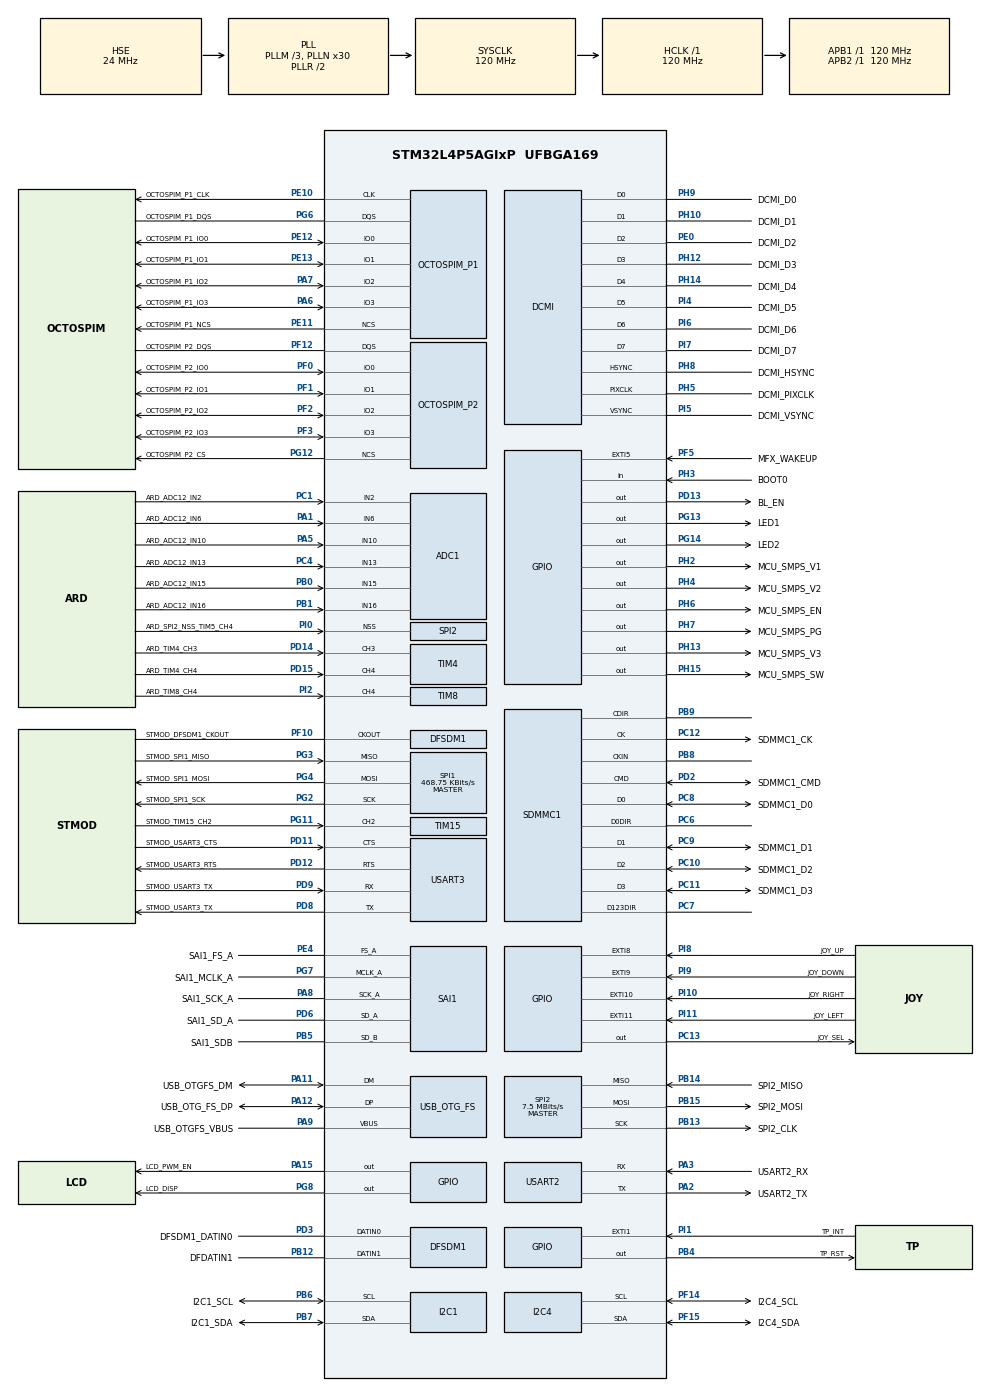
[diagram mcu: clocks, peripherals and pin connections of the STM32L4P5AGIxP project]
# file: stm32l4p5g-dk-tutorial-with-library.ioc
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ADC1.Channel-0\#ChannelRegularConversion=ADC_CHANNEL_13
ADC1.NbrOfConversionFlag=1
ADC1.OffsetNumber-0\#ChannelRegularConversion=ADC_OFFSET_NONE
ADC1.Rank-0\#ChannelRegularConversion=1
ADC1.SamplingTime-0\#ChannelRegularConversion=ADC_SAMPLETIME_2CYCLES_5
ADC1.master=1
I2C1.Timing=0x307075B1
I2C4.Timing=0x307075B1
Mcu.Family=STM32L4
Mcu.Name=STM32L4P5AGIxP
Mcu.Package=UFBGA169
NVIC.PriorityGroup=NVIC_PRIORITYGROUP_4
PA1.GPIO_Label=ARD_ADC12_IN6
PA1.Signal=ADCx_IN6
PA10.GPIO_Label=USB_OTGFS_ID
PA10.Signal=USB_OTG_FS_ID
PA11.GPIO_Label=USB_OTGFS_DM
PA11.Mode=Device_Only
PA11.Signal=USB_OTG_FS_DM
PA12.GPIO_Label=USB_OTG_FS_DP
PA12.Mode=Device_Only
PA12.Signal=USB_OTG_FS_DP
PA13\ (JTMS/SWDIO).GPIO_Label=SWDIO
PA13\ (JTMS/SWDIO).Mode=Trace_Asynchronous_SW
PA13\ (JTMS/SWDIO).Signal=SYS_JTMS-SWDIO
PA14\ (JTCK/SWCLK).GPIO_Label=SWCLK
PA14\ (JTCK/SWCLK).Mode=Trace_Asynchronous_SW
PA14\ (JTCK/SWCLK).Signal=SYS_JTCK-SWCLK
PA15\ (JTDI).GPIO_Label=LCD_PWM_EN
PA15\ (JTDI).Signal=GPIO_Output
PA2.GPIO_Label=USART2_TX
PA2.Mode=Asynchronous
PA2.Signal=USART2_TX
PA3.GPIO_Label=USART2_RX
PA3.Mode=Asynchronous
PA3.Signal=USART2_RX
PA4.GPIO_Label=LCD_CLK
PA4.Signal=LTDC_CLK
PA5.GPIO_Label=ARD_ADC12_IN10
PA5.Signal=ADCx_IN10
PA6.GPIO_Label=OCTOSPIM_P1_IO3
PA6.Mode=OCTOSPI2_IOH_Port1L
PA6.Signal=OCTOSPIM_P1_IO3
PA7.GPIO_Label=OCTOSPIM_P1_IO2
PA7.Mode=OCTOSPI2_IOH_Port1L
PA7.Signal=OCTOSPIM_P1_IO2
PA8.GPIO_Label=SAI1_SCK_A
PA8.Mode=SAI_A_MasterWithClock
PA8.Signal=SAI1_SCK_A
PA9.GPIO_Label=USB_OTGFS_VBUS
PA9.Mode=Activate_VBUS
PA9.Signal=USB_OTG_FS_VBUS
PB0.GPIO_Label=ARD_ADC12_IN15
PB0.Signal=ADCx_IN15
PB1.GPIO_Label=ARD_ADC12_IN16
PB1.Signal=ADCx_IN16
PB12.GPIO_Label=DFDATIN1
PB12.Signal=S_DATAIN1DFSDM1
PB13.GPIO_Label=SPI2_CLK
PB13.Mode=Full_Duplex_Master
PB13.Signal=SPI2_SCK
PB14.GPIO_Label=SPI2_MISO
PB14.Mode=Full_Duplex_Master
PB14.Signal=SPI2_MISO
PB15.GPIO_Label=SPI2_MOSI
PB15.Mode=Full_Duplex_Master
PB15.Signal=SPI2_MOSI
PB2.GPIO_Label=LCD_RTC_OUT2
PB2.Signal=LPTIM1_OUT
PB3\ (JTDO/TRACESWO).GPIO_Label=SWO
PB3\ (JTDO/TRACESWO).Mode=Trace_Asynchronous_SW
PB3\ (JTDO/TRACESWO).Signal=SYS_JTDO-SWO
PB4\ (NJTRST).GPIO_Label=TP_RST
PB4\ (NJTRST).Signal=GPIO_Output
PB5.GPIO_Label=SAI1_SDB
PB5.Mode=SAI_B_SyncSlave
PB5.Signal=SAI1_SD_B
PB6.GPIO_Label=I2C1_SCL
PB6.Mode=I2C
PB6.Signal=I2C1_SCL
PB7.GPIO_Label=I2C1_SDA
PB7.Mode=I2C
PB7.Signal=I2C1_SDA
PB8.Mode=SD_4_bits_Wide_bus_dir_voltage_converter
PB8.Signal=SDMMC1_CKIN
PB9.Mode=SD_4_bits_Wide_bus_dir_voltage_converter
PB9.Signal=SDMMC1_CDIR
PC0.GPIO_Label=LCD_DE
PC0.Signal=LTDC_DE
PC1.GPIO_Label=ARD_ADC12_IN2
PC1.Signal=ADCx_IN2
PC10.GPIO_Label=SDMMC1_D2
PC10.Mode=SD_4_bits_Wide_bus_dir_voltage_converter
PC10.Signal=SDMMC1_D2
PC11.GPIO_Label=SDMMC1_D3
PC11.Mode=SD_4_bits_Wide_bus_dir_voltage_converter
PC11.Signal=SDMMC1_D3
PC12.GPIO_Label=SDMMC1_CK
PC12.Mode=SD_4_bits_Wide_bus_dir_voltage_converter
PC12.Signal=SDMMC1_CK
PC13.GPIO_Label=JOY_SEL
PC13.Signal=GPIO_Output
PC14-OSC32_IN\ (PC14).Mode=LSE-External-Oscillator
PC14-OSC32_IN\ (PC14).Signal=RCC_OSC32_IN
PC15-OSC32_OUT\ (PC15).Mode=LSE-External-Oscillator
PC15-OSC32_OUT\ (PC15).Signal=RCC_OSC32_OUT
PC2.GPIO_Label=LCD_HSYNC
PC2.Signal=LTDC_HSYNC
PC4.GPIO_Label=ARD_ADC12_IN13
PC4.Signal=ADCx_IN13
PC6.Mode=SD_4_bits_Wide_bus_dir_voltage_converter
PC6.Signal=SDMMC1_D0DIR
PC7.Mode=SD_4_bits_Wide_bus_dir_voltage_converter
PC7.Signal=SDMMC1_D123DIR
PC8.GPIO_Label=SDMMC1_D0
PC8.Mode=SD_4_bits_Wide_bus_dir_voltage_converter
PC8.Signal=SDMMC1_D0
PC9.GPIO_Label=SDMMC1_D1
PC9.Mode=SD_4_bits_Wide_bus_dir_voltage_converter
PC9.Signal=SDMMC1_D1
PD10.GPIO_Label=STMOD_INT
PD10.Signal=EVENTOUT
PD11.GPIO_Label=STMOD_USART3_CTS
PD11.Mode=CTS_RTS
PD11.Signal=USART3_CTS
PD12.GPIO_Label=STMOD_USART3_RTS
PD12.Mode=CTS_RTS
PD12.Signal=USART3_RTS
PD13.GPIO_Label=BL_EN
PD13.Signal=GPIO_Output
PD14.GPIO_Label=ARD_TIM4_CH3
PD14.Signal=S_TIM4_CH3
PD15.GPIO_Label=ARD_TIM4_CH4
PD15.Signal=S_TIM4_CH4
PD2.GPIO_Label=SDMMC1_CMD
PD2.Mode=SD_4_bits_Wide_bus_dir_voltage_converter
PD2.Signal=SDMMC1_CMD
PD3.GPIO_Label=DFSDM1_DATIN0
PD3.Signal=S_DATAIN0DFSDM1
PD6.GPIO_Label=SAI1_SD_A
PD6.Mode=SAI_A_MasterWithClock
PD6.Signal=SAI1_SD_A
PD8.GPIO_Label=STMOD_USART3_TX
PD8.Mode=Asynchronous
PD8.Signal=USART3_TX
PD9.GPIO_Label=STMOD_USART3_TX
PD9.Mode=Asynchronous
PD9.Signal=USART3_RX
PE0.GPIO_Label=DCMI_D2
PE0.Mode=Slave_8_bits_External_Synchro
PE0.Signal=DCMI_D2
PE1.GPIO_Label=LCD_VSYNC
PE1.Signal=LTDC_VSYNC
PE10.GPIO_Label=OCTOSPIM_P1_CLK
PE10.Mode=O1_P1_CLK
PE10.Signal=OCTOSPIM_P1_CLK
PE11.GPIO_Label=OCTOSPIM_P1_NCS
PE11.Mode=OCTOSPI1_Port1_NCS
PE11.Signal=OCTOSPIM_P1_NCS
PE12.GPIO_Label=OCTOSPIM_P1_IO0
PE12.Mode=OCTOSPI2_IOH_Port1L
PE12.Signal=OCTOSPIM_P1_IO0
PE13.GPIO_Label=OCTOSPIM_P1_IO1
PE13.Mode=OCTOSPI2_IOH_Port1L
PE13.Signal=OCTOSPIM_P1_IO1
PE2.GPIO_Label=LCD_R7
PE2.Signal=LTDC_R7
PE3.GPIO_Label=LCD_R6
PE3.Signal=LTDC_R6
PE4.GPIO_Label=SAI1_FS_A
PE4.Mode=SAI_A_MasterWithClock
PE4.Signal=SAI1_FS_A
PE5.GPIO_Label=LCD_G7
PE5.Signal=LTDC_G7
PE6.GPIO_Label=LCD_G6
PE6.Signal=LTDC_G6
PE7.GPIO_Label=LCD_B6
PE7.Signal=LTDC_B6
PE8.GPIO_Label=LCD_B7
PE8.Signal=LTDC_B7
PF0.GPIO_Label=OCTOSPIM_P2_IO0
PF0.Mode=OCTOSPI1_IOL_Port2L
PF0.Signal=OCTOSPIM_P2_IO0
PF1.GPIO_Label=OCTOSPIM_P2_IO1
PF1.Mode=OCTOSPI1_IOL_Port2L
PF1.Signal=OCTOSPIM_P2_IO1
PF10.GPIO_Label=STMOD_DFSDM1_CKOUT
PF10.Signal=S_CKOUTDFSDM1
PF12.GPIO_Label=OCTOSPIM_P2_DQS
PF12.Mode=OCTOSPI2_Port2_DQS
PF12.Signal=OCTOSPIM_P2_DQS
PF14.GPIO_Label=I2C4_SCL
PF14.Mode=I2C
PF14.Signal=I2C4_SCL
PF15.GPIO_Label=I2C4_SDA
PF15.Mode=I2C
PF15.Signal=I2C4_SDA
PF2.GPIO_Label=OCTOSPIM_P2_IO2
PF2.Mode=OCTOSPI1_IOL_Port2L
PF2.Signal=OCTOSPIM_P2_IO2
PF3.GPIO_Label=OCTOSPIM_P2_IO3
PF3.Mode=OCTOSPI1_IOL_Port2L
PF3.Signal=OCTOSPIM_P2_IO3
PF5.GPIO_Label=MFX_WAKEUP
PF5.Signal=GPXTI5
PG11.GPIO_Label=STMOD_TIM15_CH2
PG11.Signal=S_TIM15_CH2
PG12.GPIO_Label=OCTOSPIM_P2_CS
PG12.Mode=OCTOSPI2_Port2_NCS
PG12.Signal=OCTOSPIM_P2_NCS
PG13.GPIO_Label=LED1
PG13.Signal=GPIO_Output
PG14.GPIO_Label=LED2
PG14.Signal=GPIO_Output
PG2.GPIO_Label=STMOD_SPI1_SCK
PG2.Mode=Full_Duplex_Master
PG2.Signal=SPI1_SCK
PG3.GPIO_Label=STMOD_SPI1_MISO
PG3.Mode=Full_Duplex_Master
PG3.Signal=SPI1_MISO
PG4.GPIO_Label=STMOD_SPI1_MOSI
PG4.Mode=Full_Duplex_Master
PG4.Signal=SPI1_MOSI
PG5.GPIO_Label=STMOD_SPI1_NSS
PG5.Signal=FMC_A15
PG6.GPIO_Label=OCTOSPIM_P1_DQS
PG6.Mode=OCTOSPI1_Port1_DQS
PG6.Signal=OCTOSPIM_P1_DQS
PG7.GPIO_Label=SAI1_MCLK_A
PG7.Mode=SAI_A_MasterWithClock
PG7.Signal=SAI1_MCLK_A
PG8.GPIO_Label=LCD_DISP
PG8.Signal=GPIO_Output
PH0-OSC_IN\ (PH0).Mode=HSE-External-Oscillator
PH0-OSC_IN\ (PH0).Signal=RCC_OSC_IN
PH1-OSC_OUT\ (PH1).Mode=HSE-External-Oscillator
PH1-OSC_OUT\ (PH1).Signal=RCC_OSC_OUT
PH10.GPIO_Label=DCMI_D1
PH10.Mode=Slave_8_bits_External_Synchro
PH10.Signal=DCMI_D1
PH12.GPIO_Label=DCMI_D3
PH12.Mode=Slave_8_bits_External_Synchro
PH12.Signal=DCMI_D3
PH13.GPIO_Label=MCU_SMPS_V3
PH13.Signal=GPIO_Output
PH14.GPIO_Label=DCMI_D4
PH14.Mode=Slave_8_bits_External_Synchro
PH14.Signal=DCMI_D4
PH15.GPIO_Label=MCU_SMPS_SW
PH15.Signal=GPIO_Output
PH2.GPIO_Label=MCU_SMPS_V1
PH2.Signal=GPIO_Output
PH3-BOOT0.GPIO_Label=BOOT0
PH3-BOOT0.Signal=GPIO_Input
PH4.GPIO_Label=MCU_SMPS_V2
PH4.Signal=GPIO_Output
PH5.GPIO_Label=DCMI_PIXCLK
PH5.Mode=Slave_8_bits_External_Synchro
PH5.Signal=DCMI_PIXCLK
PH6.GPIO_Label=MCU_SMPS_EN
PH6.Signal=GPIO_Output
PH7.GPIO_Label=MCU_SMPS_PG
PH7.Signal=GPIO_Output
PH8.GPIO_Label=DCMI_HSYNC
PH8.Mode=Slave_8_bits_External_Synchro
PH8.Signal=DCMI_HSYNC
PH9.GPIO_Label=DCMI_D0
PH9.Mode=Slave_8_bits_External_Synchro
PH9.Signal=DCMI_D0
PI0.GPIO_Label=ARD_SPI2_NSS_TIM5_CH4
PI0.Signal=SharedStack_PI0
PI0.Stacked=true
PI1.GPIO_Label=TP_INT
PI1.Signal=GPXTI1
PI10.GPIO_Label=JOY_RIGHT
PI10.Signal=GPXTI10
PI11.GPIO_Label=JOY_LEFT
PI11.Signal=GPXTI11
PI2.GPIO_Label=ARD_TIM8_CH4
PI2.Signal=S_TIM8_CH4
PI3.GPIO_Label=DCMI_D10
PI3.Signal=DCMI_D10
PI4.GPIO_Label=DCMI_D5
PI4.Mode=Slave_8_bits_External_Synchro
PI4.Signal=DCMI_D5
PI5.GPIO_Label=DCMI_VSYNC
PI5.Mode=Slave_8_bits_External_Synchro
PI5.Signal=DCMI_VSYNC
PI6.GPIO_Label=DCMI_D6
PI6.Mode=Slave_8_bits_External_Synchro
PI6.Signal=DCMI_D6
PI7.GPIO_Label=DCMI_D7
PI7.Mode=Slave_8_bits_External_Synchro
PI7.Signal=DCMI_D7
PI8.GPIO_Label=JOY_UP
PI8.Signal=GPXTI8
PI9.GPIO_Label=JOY_DOWN
PI9.Signal=GPXTI9
ProjectManager.HeapSize=0x200
ProjectManager.StackSize=0x400
ProjectManager.TargetToolchain=STM32CubeIDE
RCC.ADCFreq_Value=48000000
RCC.AHBFreq_Value=120000000
RCC.APB1Freq_Value=120000000
RCC.APB1TimFreq_Value=120000000
RCC.APB2Freq_Value=120000000
RCC.APB2TimFreq_Value=120000000
RCC.CortexFreq_Value=120000000
RCC.HCLKFreq_Value=120000000
RCC.HSE_VALUE=24000000
RCC.HSI48_VALUE=48000000
RCC.HSI_VALUE=16000000
RCC.MSI_VALUE=4000000
RCC.PLLM1=3
RCC.PLLM2=3
RCC.PLLN=30
RCC.PLLSAI1N=12
RCC.PLLSourceVirtual=RCC_PLLSOURCE_HSE
RCC.SYSCLKFreq_VALUE=120000000
RCC.SYSCLKSource=RCC_SYSCLKSOURCE_PLLCLK
RCC.USBFreq_Value=48000000
RCC.VCOOutputFreq_Value=240000000
SAI1.ErrorAudioFreq-SAI_A_MasterWithClock=-81.39 %
SAI1.Instance-SAI_A_MasterWithClock=SAI$Index_Block_A
SAI1.Instance-SAI_B_SyncSlave=SAI$Index_Block_B
SAI1.MClockEnable-SAI_A_MasterWithClock=SAI_MASTERCLOCK_ENABLE
SAI1.RealAudioFreq-SAI_A_MasterWithClock=35.714 KHz
SAI1.VirtualMode-SAI_A_MasterWithClock=VM_MASTER
SAI1.VirtualMode-SAI_B_SyncSlave=VM_SLAVE
SH.ADCx_IN10.0=ADC1_IN10,IN10-Single-Ended
SH.ADCx_IN13.0=ADC1_IN13,IN13-Single-Ended
SH.ADCx_IN15.0=ADC1_IN15,IN15-Single-Ended
SH.ADCx_IN16.0=ADC1_IN16,IN16-Single-Ended
SH.ADCx_IN2.0=ADC1_IN2,IN2-Single-Ended
SH.ADCx_IN6.0=ADC1_IN6,IN6-Single-Ended
SH.FMC_A15.0=FMC_A15
SH.S_CKOUTDFSDM1.0=DFSDM1_CKOUT,CKOUT
SH.S_CKOUTDFSDM1.1=DFSDM1_CKOUT,PDM_SPI_input_from_ch0_and_internal_clock
SH.S_CKOUTDFSDM1.2=DFSDM1_CKOUT,PDM_SPI_input_from_ch1_and_internal_clock
SH.S_DATAIN0DFSDM1.0=DFSDM1_DATIN0,PDM_SPI_input_from_ch0_and_internal_clock
SH.S_DATAIN1DFSDM1.0=DFSDM1_DATIN1,PDM_SPI_input_from_ch1_and_internal_clock
SH.S_TIM15_CH2.0=TIM15_CH2,Input_Capture2_from_TI2
SH.S_TIM4_CH3.0=TIM4_CH3,Input_Capture3_from_TI3
SH.S_TIM4_CH4.0=TIM4_CH4,Input_Capture4_from_TI4
SH.S_TIM8_CH4.0=TIM8_CH4,Input_Capture4_from_TI4
SH.SharedStack_PI0.0=SPI2_NSS,NSS_Signal_Hard_Input
SH.SharedStack_PI0.1=TIM5_CH4
SPI1.BaudRatePrescaler=SPI_BAUDRATEPRESCALER_256
SPI1.CalculateBaudRate=468.75 KBits/s
SPI1.Direction=SPI_DIRECTION_2LINES
SPI1.Mode=SPI_MODE_MASTER
SPI1.VirtualType=VM_MASTER
SPI2.BaudRatePrescaler=SPI_BAUDRATEPRESCALER_16
SPI2.CalculateBaudRate=7.5 MBits/s
SPI2.Direction=SPI_DIRECTION_2LINES
SPI2.Mode=SPI_MODE_MASTER
SPI2.VirtualNSS=VM_NSSHARD
SPI2.VirtualType=VM_MASTER
TIM15.Channel-Input_Capture2_from_TI2=TIM_CHANNEL_2
TIM4.Channel-Input_Capture3_from_TI3=TIM_CHANNEL_3
TIM4.Channel-Input_Capture4_from_TI4=TIM_CHANNEL_4
TIM8.Channel-Input_Capture4_from_TI4=TIM_CHANNEL_4
USART2.VirtualMode-Asynchronous=VM_ASYNC
USART3.VirtualMode-Asynchronous=VM_ASYNC
USB_OTG_FS.VirtualMode=Device_Only
VP_OCTOSPI1_VS_octo.Mode=octo_mode
VP_OCTOSPI2_VS_octo.Mode=octo_mode
board=STM32L4P5G-DK

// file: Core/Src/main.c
/* USER CODE BEGIN Header */
/**
  ******************************************************************************
  * @file           : main.c
  * @brief          : Main program body
  ******************************************************************************
  * @attention
  *
  * <h2><center>&copy; Copyright (c) 2020 STMicroelectronics.
  * All rights reserved.</center></h2>
  *
  * This software component is licensed by ST under BSD 3-Clause license,
  * the "License"; You may not use this file except in compliance with the
  * License. You may obtain a copy of the License at:
  *                        opensource.org/licenses/BSD-3-Clause
  *
  ******************************************************************************
  */
/* USER CODE END Header */
#include "main.h"

/* USER CODE BEGIN Includes */
// C Includes
#include <stdbool.h>
#include <stddef.h>
#include <stdint.h>
#include <stdio.h>
#include <stdlib.h>
#include <string.h>

// 3rd-Party Includes
#include <bme680.h>
#include <note.h>
/* USER CODE END Includes */

/* USER CODE BEGIN PTD */
#define DELAY_PERIOD_MS (15*1000) // 15 seconds
#define NOTE_I2C_BUFFER_SIZE 0xFF

#ifndef PRODUCT_UID
#pragma info "PRODUCT_UID is not defined in this example. Please ensure your Notecard has a product identifier set before running this example or define it in code here. Please see https://bit.ly/product-uid for more details."
#define PRODUCT_UID ""      /* com.mycompany.myname:project */

#endif

/* USER CODE END PTD */

ADC_HandleTypeDef hadc1;

DCMI_HandleTypeDef hdcmi;

DFSDM_Channel_HandleTypeDef hdfsdm1_channel0;
DFSDM_Channel_HandleTypeDef hdfsdm1_channel1;

I2C_HandleTypeDef hi2c1;
I2C_HandleTypeDef hi2c4;

OSPI_HandleTypeDef hospi1;
OSPI_HandleTypeDef hospi2;

SAI_HandleTypeDef hsai_BlockA1;
SAI_HandleTypeDef hsai_BlockB1;

SD_HandleTypeDef hsd1;

SPI_HandleTypeDef hspi1;
SPI_HandleTypeDef hspi2;

TIM_HandleTypeDef htim4;
TIM_HandleTypeDef htim8;
TIM_HandleTypeDef htim15;

UART_HandleTypeDef huart2;
UART_HandleTypeDef huart3;

PCD_HandleTypeDef hpcd_USB_OTG_FS;

/* USER CODE BEGIN PV */
// Data used during BME680 sampling
struct bme680_dev gas_sensor;
char i2c_reading_buf[100];
int8_t rslt = BME680_OK;

// Necessary for Notecard I/O functionality
bool i2c4Initialized = false;
/* USER CODE END PV */

void SystemClock_Config(void);
static void MX_GPIO_Init(void);
static void MX_ADC1_Init(void);
static void MX_DCMI_Init(void);
static void MX_DFSDM1_Init(void);
static void MX_I2C1_Init(void);
static void MX_I2C4_Init(void);
static void MX_OCTOSPI1_Init(void);
static void MX_OCTOSPI2_Init(void);
static void MX_SAI1_Init(void);
static void MX_SDMMC1_SD_Init(void);
static void MX_SPI1_Init(void);
static void MX_SPI2_Init(void);
static void MX_TIM4_Init(void);
static void MX_TIM8_Init(void);
static void MX_TIM15_Init(void);
static void MX_USART2_UART_Init(void);
static void MX_USART3_UART_Init(void);
static void MX_USB_OTG_FS_PCD_Init(void);
/* USER CODE BEGIN PFP */
void MX_I2C4_DeInit(void);

// BME680 Forward Declarations
int8_t bme680I2cRead(uint8_t dev_id, uint8_t reg_addr, uint8_t *reg_data, uint16_t len);
int8_t bme680I2cWrite(uint8_t dev_id, uint8_t reg_addr, uint8_t *reg_data, uint16_t len);

// Note I2C Interface
bool noteI2CReset(uint16_t dev_addr);
const char * noteI2CTransmit(uint16_t dev_addr, uint8_t* pBuffer, uint16_t size);
const char * noteI2CReceive(uint16_t dev_addr, uint8_t* pBuffer, uint16_t size, uint32_t *available);

// Serial Debug
size_t noteDebugSerialOutput(const char *message);
/* USER CODE END PFP */

int main(void)
{

  /* MCU Configuration--------------------------------------------------------*/

  /* Reset of all peripherals, Initializes the Flash interface and the Systick. */
  HAL_Init();

  /* Configure the system clock */
  SystemClock_Config();

  /* Initialize all configured peripherals */
  MX_GPIO_Init();
  MX_ADC1_Init();
  MX_DCMI_Init();
  MX_DFSDM1_Init();
  MX_I2C1_Init();
  MX_I2C4_Init();
  MX_OCTOSPI1_Init();
  MX_OCTOSPI2_Init();
  MX_SAI1_Init();
  MX_SDMMC1_SD_Init();
  MX_SPI1_Init();
  MX_SPI2_Init();
  MX_TIM4_Init();
  MX_TIM8_Init();
  MX_TIM15_Init();
  MX_USART2_UART_Init();
  MX_USART3_UART_Init();
  MX_USB_OTG_FS_PCD_Init();
  /* USER CODE BEGIN 2 */
  // Configure the BME680 driver
  gas_sensor.dev_id = BME680_I2C_ADDR_PRIMARY;
  gas_sensor.intf = BME680_I2C_INTF;
  gas_sensor.read = bme680I2cRead;
  gas_sensor.write = bme680I2cWrite;
  gas_sensor.delay_ms = HAL_Delay;
  gas_sensor.amb_temp = 25;

  // Initialize the driver
  if (bme680_init(&gas_sensor) != BME680_OK) {
    char bme_msg[] = "BME680 Initialization Error\\r\\n";
    noteDebugSerialOutput(bme_msg);
  } else {
    char bme_msg[] = "BME680 Initialized and Ready\\r\\n";
    noteDebugSerialOutput(bme_msg);
  }

  // Select desired oversampling rates
  gas_sensor.tph_sett.os_hum = BME680_OS_2X;
  gas_sensor.tph_sett.os_pres = BME680_OS_4X;
  gas_sensor.tph_sett.os_temp = BME680_OS_8X;

  // Set sensor to "always on"
  gas_sensor.power_mode = BME680_FORCED_MODE;

  // Set oversampling settings
  uint8_t required_settings = (BME680_OST_SEL | BME680_OSP_SEL | BME680_OSH_SEL);
  rslt = bme680_set_sensor_settings(required_settings, &gas_sensor);

  // Set sensor mode
  rslt = bme680_set_sensor_mode(&gas_sensor);

  // Query minimum sampling period
  uint16_t min_sampling_period;
  bme680_get_profile_dur(&min_sampling_period, &gas_sensor);

  // Sampling results variable
  struct bme680_field_data data;

  // Set Notecard System Interface
  NoteSetFn(malloc, free, HAL_Delay, HAL_GetTick);

  // Set Notecard I2C Interface
  NoteSetFnI2C(NOTE_I2C_ADDR_DEFAULT, NOTE_I2C_BUFFER_SIZE, noteI2CReset, noteI2CTransmit, noteI2CReceive);

  // Configure device with ProductUID
  J *req = NoteNewRequest("hub.set");
  if (PRODUCT_UID[0]) {
    JAddStringToObject(req, "product", PRODUCT_UID);
  }
  JAddStringToObject(req, "mode", "continuous");
  NoteRequest(req);
  /* USER CODE END 2 */

  /* Infinite loop */
  /* USER CODE BEGIN WHILE */
  while (1)
  {
	  // Allow BME680 to sample environment
	  HAL_Delay(min_sampling_period);

	  // Query the sample data
	  rslt = bme680_get_sensor_data(&data, &gas_sensor);

	  // Format results into a human readable string
	  sprintf(i2c_reading_buf,
	    "T: %u.%u degC, H %u.%u %%rH\\r\\n",
	    (unsigned int)data.temperature / 100,
	    (unsigned int)data.temperature % 100,
	    (unsigned int)data.humidity / 1000,
	    (unsigned int)data.humidity % 1000);

	  // Publish result to connected PC
	  noteDebugSerialOutput(i2c_reading_buf);

	  // Queue sensor reading to Notecard
	  J *req = NoteNewRequest("note.add");
	  if (req != NULL) {
	    JAddStringToObject(req, "file", "sensors.qo");
	    JAddBoolToObject(req, "sync", true);
	    J *body = JCreateObject();
	    if (body != NULL) {
	      JAddNumberToObject(body, "temp", data.temperature / 100.0);
	      JAddNumberToObject(body, "humidity", data.humidity / 1000.0);
	      JAddItemToObject(req, "body", body);
	    }
	    NoteRequest(req);
	  }

	  // Wait between samples
	  HAL_Delay(DELAY_PERIOD_MS);

	  // Request the next sample
	  if (gas_sensor.power_mode == BME680_FORCED_MODE) {
	    rslt = bme680_set_sensor_mode(&gas_sensor);
	  }
    /* USER CODE END WHILE */

  }
}

void SystemClock_Config(void)
{
  RCC_OscInitTypeDef RCC_OscInitStruct = {0};
  RCC_ClkInitTypeDef RCC_ClkInitStruct = {0};
  RCC_PeriphCLKInitTypeDef PeriphClkInit = {0};

  /** Configure the main internal regulator output voltage
  */
  if (HAL_PWREx_ControlVoltageScaling(PWR_REGULATOR_VOLTAGE_SCALE1_BOOST) != HAL_OK)
  {
    Error_Handler();
  }
  /** Initializes the RCC Oscillators according to the specified parameters
  * in the RCC_OscInitTypeDef structure.
  */
  RCC_OscInitStruct.OscillatorType = RCC_OSCILLATORTYPE_HSE;
  RCC_OscInitStruct.HSEState = RCC_HSE_ON;
  RCC_OscInitStruct.PLL.PLLState = RCC_PLL_ON;
  RCC_OscInitStruct.PLL.PLLSource = RCC_PLLSOURCE_HSE;
  RCC_OscInitStruct.PLL.PLLM = 3;
  RCC_OscInitStruct.PLL.PLLN = 30;
  RCC_OscInitStruct.PLL.PLLP = RCC_PLLP_DIV7;
  RCC_OscInitStruct.PLL.PLLQ = RCC_PLLQ_DIV2;
  RCC_OscInitStruct.PLL.PLLR = RCC_PLLR_DIV2;
  if (HAL_RCC_OscConfig(&RCC_OscInitStruct) != HAL_OK)
  {
    Error_Handler();
  }
  /** Initializes the CPU, AHB and APB buses clocks
  */
  RCC_ClkInitStruct.ClockType = RCC_CLOCKTYPE_HCLK|RCC_CLOCKTYPE_SYSCLK
                              |RCC_CLOCKTYPE_PCLK1|RCC_CLOCKTYPE_PCLK2;
  RCC_ClkInitStruct.SYSCLKSource = RCC_SYSCLKSOURCE_PLLCLK;
  RCC_ClkInitStruct.AHBCLKDivider = RCC_SYSCLK_DIV1;
  RCC_ClkInitStruct.APB1CLKDivider = RCC_HCLK_DIV1;
  RCC_ClkInitStruct.APB2CLKDivider = RCC_HCLK_DIV1;

  if (HAL_RCC_ClockConfig(&RCC_ClkInitStruct, FLASH_LATENCY_5) != HAL_OK)
  {
    Error_Handler();
  }
  PeriphClkInit.PeriphClockSelection = RCC_PERIPHCLK_USART2|RCC_PERIPHCLK_USART3
                              |RCC_PERIPHCLK_SAI1|RCC_PERIPHCLK_I2C1
                              |RCC_PERIPHCLK_I2C4|RCC_PERIPHCLK_DFSDM1
                              |RCC_PERIPHCLK_USB|RCC_PERIPHCLK_SDMMC1
                              |RCC_PERIPHCLK_ADC|RCC_PERIPHCLK_OSPI;
  PeriphClkInit.Usart2ClockSelection = RCC_USART2CLKSOURCE_PCLK1;
  PeriphClkInit.Usart3ClockSelection = RCC_USART3CLKSOURCE_PCLK1;
  PeriphClkInit.I2c1ClockSelection = RCC_I2C1CLKSOURCE_PCLK1;
  PeriphClkInit.I2c4ClockSelection = RCC_I2C4CLKSOURCE_PCLK1;
  PeriphClkInit.Sai1ClockSelection = RCC_SAI1CLKSOURCE_PLLSAI1;
  PeriphClkInit.AdcClockSelection = RCC_ADCCLKSOURCE_PLLSAI1;
  PeriphClkInit.Dfsdm1ClockSelection = RCC_DFSDM1CLKSOURCE_PCLK;
  PeriphClkInit.OspiClockSelection = RCC_OSPICLKSOURCE_SYSCLK;
  PeriphClkInit.UsbClockSelection = RCC_USBCLKSOURCE_PLLSAI1;
  PeriphClkInit.Sdmmc1ClockSelection = RCC_SDMMC1CLKSOURCE_PLLP;
  PeriphClkInit.PLLSAI1.PLLSAI1Source = RCC_PLLSOURCE_HSE;
  PeriphClkInit.PLLSAI1.PLLSAI1M = 3;
  PeriphClkInit.PLLSAI1.PLLSAI1N = 12;
  PeriphClkInit.PLLSAI1.PLLSAI1P = RCC_PLLP_DIV7;
  PeriphClkInit.PLLSAI1.PLLSAI1Q = RCC_PLLQ_DIV2;
  PeriphClkInit.PLLSAI1.PLLSAI1R = RCC_PLLR_DIV2;
  PeriphClkInit.PLLSAI1.PLLSAI1ClockOut = RCC_PLLSAI1_SAI1CLK|RCC_PLLSAI1_48M2CLK
                              |RCC_PLLSAI1_ADC1CLK;
  if (HAL_RCCEx_PeriphCLKConfig(&PeriphClkInit) != HAL_OK)
  {
    Error_Handler();
  }
}

static void MX_ADC1_Init(void)
{

  ADC_MultiModeTypeDef multimode = {0};
  ADC_ChannelConfTypeDef sConfig = {0};

  /** Common config
  */
  hadc1.Instance = ADC1;
  hadc1.Init.ClockPrescaler = ADC_CLOCK_ASYNC_DIV1;
  hadc1.Init.Resolution = ADC_RESOLUTION_12B;
  hadc1.Init.DataAlign = ADC_DATAALIGN_RIGHT;
  hadc1.Init.ScanConvMode = ADC_SCAN_DISABLE;
  hadc1.Init.EOCSelection = ADC_EOC_SINGLE_CONV;
  hadc1.Init.LowPowerAutoWait = DISABLE;
  hadc1.Init.ContinuousConvMode = DISABLE;
  hadc1.Init.NbrOfConversion = 1;
  hadc1.Init.DiscontinuousConvMode = DISABLE;
  hadc1.Init.ExternalTrigConv = ADC_SOFTWARE_START;
  hadc1.Init.ExternalTrigConvEdge = ADC_EXTERNALTRIGCONVEDGE_NONE;
  hadc1.Init.DMAContinuousRequests = DISABLE;
  hadc1.Init.Overrun = ADC_OVR_DATA_PRESERVED;
  hadc1.Init.OversamplingMode = DISABLE;
  if (HAL_ADC_Init(&hadc1) != HAL_OK)
  {
    Error_Handler();
  }
  /** Configure the ADC multi-mode
  */
  multimode.Mode = ADC_MODE_INDEPENDENT;
  if (HAL_ADCEx_MultiModeConfigChannel(&hadc1, &multimode) != HAL_OK)
  {
    Error_Handler();
  }
  /** Configure Regular Channel
  */
  sConfig.Channel = ADC_CHANNEL_13;
  sConfig.Rank = ADC_REGULAR_RANK_1;
  sConfig.SamplingTime = ADC_SAMPLETIME_2CYCLES_5;
  sConfig.SingleDiff = ADC_SINGLE_ENDED;
  sConfig.OffsetNumber = ADC_OFFSET_NONE;
  sConfig.Offset = 0;
  if (HAL_ADC_ConfigChannel(&hadc1, &sConfig) != HAL_OK)
  {
    Error_Handler();
  }

}

static void MX_DCMI_Init(void)
{

  hdcmi.Instance = DCMI;
  hdcmi.Init.SynchroMode = DCMI_SYNCHRO_HARDWARE;
  hdcmi.Init.PCKPolarity = DCMI_PCKPOLARITY_FALLING;
  hdcmi.Init.VSPolarity = DCMI_VSPOLARITY_LOW;
  hdcmi.Init.HSPolarity = DCMI_HSPOLARITY_LOW;
  hdcmi.Init.CaptureRate = DCMI_CR_ALL_FRAME;
  hdcmi.Init.ExtendedDataMode = DCMI_EXTEND_DATA_8B;
  hdcmi.Init.JPEGMode = DCMI_JPEG_DISABLE;
  hdcmi.Init.ByteSelectMode = DCMI_BSM_ALL;
  hdcmi.Init.ByteSelectStart = DCMI_OEBS_ODD;
  hdcmi.Init.LineSelectMode = DCMI_LSM_ALL;
  hdcmi.Init.LineSelectStart = DCMI_OELS_ODD;
  if (HAL_DCMI_Init(&hdcmi) != HAL_OK)
  {
    Error_Handler();
  }

}

static void MX_DFSDM1_Init(void)
{

  hdfsdm1_channel0.Instance = DFSDM1_Channel0;
  hdfsdm1_channel0.Init.OutputClock.Activation = ENABLE;
  hdfsdm1_channel0.Init.OutputClock.Selection = DFSDM_CHANNEL_OUTPUT_CLOCK_SYSTEM;
  hdfsdm1_channel0.Init.OutputClock.Divider = 2;
  hdfsdm1_channel0.Init.Input.Multiplexer = DFSDM_CHANNEL_EXTERNAL_INPUTS;
  hdfsdm1_channel0.Init.Input.DataPacking = DFSDM_CHANNEL_STANDARD_MODE;
  hdfsdm1_channel0.Init.Input.Pins = DFSDM_CHANNEL_SAME_CHANNEL_PINS;
  hdfsdm1_channel0.Init.SerialInterface.Type = DFSDM_CHANNEL_SPI_RISING;
  hdfsdm1_channel0.Init.SerialInterface.SpiClock = DFSDM_CHANNEL_SPI_CLOCK_INTERNAL;
  hdfsdm1_channel0.Init.Awd.FilterOrder = DFSDM_CHANNEL_FASTSINC_ORDER;
  hdfsdm1_channel0.Init.Awd.Oversampling = 1;
  hdfsdm1_channel0.Init.Offset = 0;
  hdfsdm1_channel0.Init.RightBitShift = 0x00;
  if (HAL_DFSDM_ChannelInit(&hdfsdm1_channel0) != HAL_OK)
  {
    Error_Handler();
  }
  hdfsdm1_channel1.Instance = DFSDM1_Channel1;
  hdfsdm1_channel1.Init.OutputClock.Activation = ENABLE;
  hdfsdm1_channel1.Init.OutputClock.Selection = DFSDM_CHANNEL_OUTPUT_CLOCK_SYSTEM;
  hdfsdm1_channel1.Init.OutputClock.Divider = 2;
  hdfsdm1_channel1.Init.Input.Multiplexer = DFSDM_CHANNEL_EXTERNAL_INPUTS;
  hdfsdm1_channel1.Init.Input.DataPacking = DFSDM_CHANNEL_STANDARD_MODE;
  hdfsdm1_channel1.Init.Input.Pins = DFSDM_CHANNEL_SAME_CHANNEL_PINS;
  hdfsdm1_channel1.Init.SerialInterface.Type = DFSDM_CHANNEL_SPI_RISING;
  hdfsdm1_channel1.Init.SerialInterface.SpiClock = DFSDM_CHANNEL_SPI_CLOCK_INTERNAL;
  hdfsdm1_channel1.Init.Awd.FilterOrder = DFSDM_CHANNEL_FASTSINC_ORDER;
  hdfsdm1_channel1.Init.Awd.Oversampling = 1;
  hdfsdm1_channel1.Init.Offset = 0;
  hdfsdm1_channel1.Init.RightBitShift = 0x00;
  if (HAL_DFSDM_ChannelInit(&hdfsdm1_channel1) != HAL_OK)
  {
    Error_Handler();
  }

}

static void MX_I2C1_Init(void)
{

  hi2c1.Instance = I2C1;
  hi2c1.Init.Timing = 0x307075B1;
  hi2c1.Init.OwnAddress1 = 0;
  hi2c1.Init.AddressingMode = I2C_ADDRESSINGMODE_7BIT;
  hi2c1.Init.DualAddressMode = I2C_DUALADDRESS_DISABLE;
  hi2c1.Init.OwnAddress2 = 0;
  hi2c1.Init.OwnAddress2Masks = I2C_OA2_NOMASK;
  hi2c1.Init.GeneralCallMode = I2C_GENERALCALL_DISABLE;
  hi2c1.Init.NoStretchMode = I2C_NOSTRETCH_DISABLE;
  if (HAL_I2C_Init(&hi2c1) != HAL_OK)
  {
    Error_Handler();
  }
  /** Configure Analogue filter
  */
  if (HAL_I2CEx_ConfigAnalogFilter(&hi2c1, I2C_ANALOGFILTER_ENABLE) != HAL_OK)
  {
    Error_Handler();
  }
  /** Configure Digital filter
  */
  if (HAL_I2CEx_ConfigDigitalFilter(&hi2c1, 0) != HAL_OK)
  {
    Error_Handler();
  }

}

static void MX_I2C4_Init(void)
{

  /* USER CODE BEGIN I2C4_Init 0 */
	// Ensure idempotence
	if (i2c4Initialized) { return; }
	i2c4Initialized = true;
  /* USER CODE END I2C4_Init 0 */

  hi2c4.Instance = I2C4;
  hi2c4.Init.Timing = 0x307075B1;
  hi2c4.Init.OwnAddress1 = 0;
  hi2c4.Init.AddressingMode = I2C_ADDRESSINGMODE_7BIT;
  hi2c4.Init.DualAddressMode = I2C_DUALADDRESS_DISABLE;
  hi2c4.Init.OwnAddress2 = 0;
  hi2c4.Init.OwnAddress2Masks = I2C_OA2_NOMASK;
  hi2c4.Init.GeneralCallMode = I2C_GENERALCALL_DISABLE;
  hi2c4.Init.NoStretchMode = I2C_NOSTRETCH_DISABLE;
  if (HAL_I2C_Init(&hi2c4) != HAL_OK)
  {
    Error_Handler();
  }
  /** Configure Analogue filter
  */
  if (HAL_I2CEx_ConfigAnalogFilter(&hi2c4, I2C_ANALOGFILTER_ENABLE) != HAL_OK)
  {
    Error_Handler();
  }
  /** Configure Digital filter
  */
  if (HAL_I2CEx_ConfigDigitalFilter(&hi2c4, 0) != HAL_OK)
  {
    Error_Handler();
  }

}

static void MX_OCTOSPI1_Init(void)
{

  OSPIM_CfgTypeDef OSPIM_Cfg_Struct = {0};

  /* OCTOSPI1 parameter configuration*/
  hospi1.Instance = OCTOSPI1;
  hospi1.Init.FifoThreshold = 1;
  hospi1.Init.DualQuad = HAL_OSPI_DUALQUAD_DISABLE;
  hospi1.Init.MemoryType = HAL_OSPI_MEMTYPE_MICRON;
  hospi1.Init.DeviceSize = 32;
  hospi1.Init.ChipSelectHighTime = 1;
  hospi1.Init.FreeRunningClock = HAL_OSPI_FREERUNCLK_DISABLE;
  hospi1.Init.ClockMode = HAL_OSPI_CLOCK_MODE_0;
  hospi1.Init.ClockPrescaler = 1;
  hospi1.Init.SampleShifting = HAL_OSPI_SAMPLE_SHIFTING_NONE;
  hospi1.Init.DelayHoldQuarterCycle = HAL_OSPI_DHQC_DISABLE;
  hospi1.Init.ChipSelectBoundary = 0;
  hospi1.Init.DelayBlockBypass = HAL_OSPI_DELAY_BLOCK_BYPASSED;
  hospi1.Init.Refresh = 0;
  if (HAL_OSPI_Init(&hospi1) != HAL_OK)
  {
    Error_Handler();
  }
  OSPIM_Cfg_Struct.ClkPort = 1;
  OSPIM_Cfg_Struct.DQSPort = 1;
  OSPIM_Cfg_Struct.NCSPort = 1;
  OSPIM_Cfg_Struct.IOLowPort = HAL_OSPIM_IOPORT_2_LOW;
  if (HAL_OSPIM_Config(&hospi1, &OSPIM_Cfg_Struct, HAL_OSPI_TIMEOUT_DEFAULT_VALUE) != HAL_OK)
  {
    Error_Handler();
  }

}

static void MX_OCTOSPI2_Init(void)
{

  OSPIM_CfgTypeDef OSPIM_Cfg_Struct = {0};

  /* OCTOSPI2 parameter configuration*/
  hospi2.Instance = OCTOSPI2;
  hospi2.Init.FifoThreshold = 1;
  hospi2.Init.DualQuad = HAL_OSPI_DUALQUAD_DISABLE;
  hospi2.Init.MemoryType = HAL_OSPI_MEMTYPE_MICRON;
  hospi2.Init.DeviceSize = 32;
  hospi2.Init.ChipSelectHighTime = 1;
  hospi2.Init.FreeRunningClock = HAL_OSPI_FREERUNCLK_DISABLE;
  hospi2.Init.ClockMode = HAL_OSPI_CLOCK_MODE_0;
  hospi2.Init.ClockPrescaler = 1;
  hospi2.Init.SampleShifting = HAL_OSPI_SAMPLE_SHIFTING_NONE;
  hospi2.Init.DelayHoldQuarterCycle = HAL_OSPI_DHQC_DISABLE;
  hospi2.Init.ChipSelectBoundary = 0;
  hospi2.Init.DelayBlockBypass = HAL_OSPI_DELAY_BLOCK_BYPASSED;
  hospi2.Init.Refresh = 0;
  if (HAL_OSPI_Init(&hospi2) != HAL_OK)
  {
    Error_Handler();
  }
  OSPIM_Cfg_Struct.DQSPort = 2;
  OSPIM_Cfg_Struct.NCSPort = 2;
  OSPIM_Cfg_Struct.IOHighPort = HAL_OSPIM_IOPORT_1_LOW;
  if (HAL_OSPIM_Config(&hospi2, &OSPIM_Cfg_Struct, HAL_OSPI_TIMEOUT_DEFAULT_VALUE) != HAL_OK)
  {
    Error_Handler();
  }

}

static void MX_SAI1_Init(void)
{

  hsai_BlockA1.Instance = SAI1_Block_A;
  hsai_BlockA1.Init.Protocol = SAI_FREE_PROTOCOL;
  hsai_BlockA1.Init.AudioMode = SAI_MODEMASTER_TX;
  hsai_BlockA1.Init.DataSize = SAI_DATASIZE_8;
  hsai_BlockA1.Init.FirstBit = SAI_FIRSTBIT_MSB;
  hsai_BlockA1.Init.ClockStrobing = SAI_CLOCKSTROBING_FALLINGEDGE;
  hsai_BlockA1.Init.Synchro = SAI_ASYNCHRONOUS;
  hsai_BlockA1.Init.OutputDrive = SAI_OUTPUTDRIVE_DISABLE;
  hsai_BlockA1.Init.NoDivider = SAI_MASTERDIVIDER_ENABLE;
  hsai_BlockA1.Init.MckOverSampling = SAI_MCK_OVERSAMPLING_DISABLE;
  hsai_BlockA1.Init.FIFOThreshold = SAI_FIFOTHRESHOLD_EMPTY;
  hsai_BlockA1.Init.AudioFrequency = SAI_AUDIO_FREQUENCY_192K;
  hsai_BlockA1.Init.SynchroExt = SAI_SYNCEXT_DISABLE;
  hsai_BlockA1.Init.MonoStereoMode = SAI_STEREOMODE;
  hsai_BlockA1.Init.CompandingMode = SAI_NOCOMPANDING;
  hsai_BlockA1.Init.TriState = SAI_OUTPUT_NOTRELEASED;
  hsai_BlockA1.Init.PdmInit.Activation = DISABLE;
  hsai_BlockA1.Init.PdmInit.MicPairsNbr = 0;
  hsai_BlockA1.Init.PdmInit.ClockEnable = SAI_PDM_CLOCK1_ENABLE;
  hsai_BlockA1.FrameInit.FrameLength = 8;
  hsai_BlockA1.FrameInit.ActiveFrameLength = 1;
  hsai_BlockA1.FrameInit.FSDefinition = SAI_FS_STARTFRAME;
  hsai_BlockA1.FrameInit.FSPolarity = SAI_FS_ACTIVE_LOW;
  hsai_BlockA1.FrameInit.FSOffset = SAI_FS_FIRSTBIT;
  hsai_BlockA1.SlotInit.FirstBitOffset = 0;
  hsai_BlockA1.SlotInit.SlotSize = SAI_SLOTSIZE_DATASIZE;
  hsai_BlockA1.SlotInit.SlotNumber = 1;
  hsai_BlockA1.SlotInit.SlotActive = 0x00000000;
  if (HAL_SAI_Init(&hsai_BlockA1) != HAL_OK)
  {
    Error_Handler();
  }
  hsai_BlockB1.Instance = SAI1_Block_B;
  hsai_BlockB1.Init.Protocol = SAI_FREE_PROTOCOL;
  hsai_BlockB1.Init.AudioMode = SAI_MODESLAVE_RX;
  hsai_BlockB1.Init.DataSize = SAI_DATASIZE_8;
  hsai_BlockB1.Init.FirstBit = SAI_FIRSTBIT_MSB;
  hsai_BlockB1.Init.ClockStrobing = SAI_CLOCKSTROBING_FALLINGEDGE;
  hsai_BlockB1.Init.Synchro = SAI_SYNCHRONOUS;
  hsai_BlockB1.Init.OutputDrive = SAI_OUTPUTDRIVE_DISABLE;
  hsai_BlockB1.Init.FIFOThreshold = SAI_FIFOTHRESHOLD_EMPTY;
  hsai_BlockB1.Init.SynchroExt = SAI_SYNCEXT_DISABLE;
  hsai_BlockB1.Init.MonoStereoMode = SAI_STEREOMODE;
  hsai_BlockB1.Init.CompandingMode = SAI_NOCOMPANDING;
  hsai_BlockB1.Init.TriState = SAI_OUTPUT_NOTRELEASED;
  hsai_BlockB1.Init.PdmInit.Activation = DISABLE;
  hsai_BlockB1.Init.PdmInit.MicPairsNbr = 0;
  hsai_BlockB1.Init.PdmInit.ClockEnable = SAI_PDM_CLOCK1_ENABLE;
  hsai_BlockB1.FrameInit.FrameLength = 8;
  hsai_BlockB1.FrameInit.ActiveFrameLength = 1;
  hsai_BlockB1.FrameInit.FSDefinition = SAI_FS_STARTFRAME;
  hsai_BlockB1.FrameInit.FSPolarity = SAI_FS_ACTIVE_LOW;
  hsai_BlockB1.FrameInit.FSOffset = SAI_FS_FIRSTBIT;
  hsai_BlockB1.SlotInit.FirstBitOffset = 0;
  hsai_BlockB1.SlotInit.SlotSize = SAI_SLOTSIZE_DATASIZE;
  hsai_BlockB1.SlotInit.SlotNumber = 1;
  hsai_BlockB1.SlotInit.SlotActive = 0x00000000;
  if (HAL_SAI_Init(&hsai_BlockB1) != HAL_OK)
  {
    Error_Handler();
  }

}

static void MX_SDMMC1_SD_Init(void)
{

  hsd1.Instance = SDMMC1;
  hsd1.Init.ClockEdge = SDMMC_CLOCK_EDGE_RISING;
  hsd1.Init.ClockPowerSave = SDMMC_CLOCK_POWER_SAVE_DISABLE;
  hsd1.Init.BusWide = SDMMC_BUS_WIDE_4B;
  hsd1.Init.HardwareFlowControl = SDMMC_HARDWARE_FLOW_CONTROL_DISABLE;
  hsd1.Init.ClockDiv = 0;
  hsd1.Init.Transceiver = SDMMC_TRANSCEIVER_ENABLE;
  if (HAL_SD_Init(&hsd1) != HAL_OK)
  {
    Error_Handler();
  }

}

static void MX_SPI1_Init(void)
{

  /* SPI1 parameter configuration*/
  hspi1.Instance = SPI1;
  hspi1.Init.Mode = SPI_MODE_MASTER;
  hspi1.Init.Direction = SPI_DIRECTION_2LINES;
  hspi1.Init.DataSize = SPI_DATASIZE_4BIT;
  hspi1.Init.CLKPolarity = SPI_POLARITY_LOW;
  hspi1.Init.CLKPhase = SPI_PHASE_1EDGE;
  hspi1.Init.NSS = SPI_NSS_SOFT;
  hspi1.Init.BaudRatePrescaler = SPI_BAUDRATEPRESCALER_256;
  hspi1.Init.FirstBit = SPI_FIRSTBIT_MSB;
  hspi1.Init.TIMode = SPI_TIMODE_DISABLE;
  hspi1.Init.CRCCalculation = SPI_CRCCALCULATION_DISABLE;
  hspi1.Init.CRCPolynomial = 7;
  hspi1.Init.CRCLength = SPI_CRC_LENGTH_DATASIZE;
  hspi1.Init.NSSPMode = SPI_NSS_PULSE_ENABLE;
  if (HAL_SPI_Init(&hspi1) != HAL_OK)
  {
    Error_Handler();
  }

}

static void MX_SPI2_Init(void)
{

  /* SPI2 parameter configuration*/
  hspi2.Instance = SPI2;
  hspi2.Init.Mode = SPI_MODE_MASTER;
  hspi2.Init.Direction = SPI_DIRECTION_2LINES;
  hspi2.Init.DataSize = SPI_DATASIZE_4BIT;
  hspi2.Init.CLKPolarity = SPI_POLARITY_LOW;
  hspi2.Init.CLKPhase = SPI_PHASE_1EDGE;
  hspi2.Init.NSS = SPI_NSS_HARD_INPUT;
  hspi2.Init.BaudRatePrescaler = SPI_BAUDRATEPRESCALER_16;
  hspi2.Init.FirstBit = SPI_FIRSTBIT_MSB;
  hspi2.Init.TIMode = SPI_TIMODE_DISABLE;
  hspi2.Init.CRCCalculation = SPI_CRCCALCULATION_DISABLE;
  hspi2.Init.CRCPolynomial = 7;
  hspi2.Init.CRCLength = SPI_CRC_LENGTH_DATASIZE;
  hspi2.Init.NSSPMode = SPI_NSS_PULSE_ENABLE;
  if (HAL_SPI_Init(&hspi2) != HAL_OK)
  {
    Error_Handler();
  }

}

static void MX_TIM4_Init(void)
{

  TIM_MasterConfigTypeDef sMasterConfig = {0};
  TIM_IC_InitTypeDef sConfigIC = {0};

  htim4.Instance = TIM4;
  htim4.Init.Prescaler = 0;
  htim4.Init.CounterMode = TIM_COUNTERMODE_UP;
  htim4.Init.Period = 65535;
  htim4.Init.ClockDivision = TIM_CLOCKDIVISION_DIV1;
  htim4.Init.AutoReloadPreload = TIM_AUTORELOAD_PRELOAD_DISABLE;
  if (HAL_TIM_IC_Init(&htim4) != HAL_OK)
  {
    Error_Handler();
  }
  sMasterConfig.MasterOutputTrigger = TIM_TRGO_RESET;
  sMasterConfig.MasterSlaveMode = TIM_MASTERSLAVEMODE_DISABLE;
  if (HAL_TIMEx_MasterConfigSynchronization(&htim4, &sMasterConfig) != HAL_OK)
  {
    Error_Handler();
  }
  sConfigIC.ICPolarity = TIM_INPUTCHANNELPOLARITY_RISING;
  sConfigIC.ICSelection = TIM_ICSELECTION_DIRECTTI;
  sConfigIC.ICPrescaler = TIM_ICPSC_DIV1;
  sConfigIC.ICFilter = 0;
  if (HAL_TIM_IC_ConfigChannel(&htim4, &sConfigIC, TIM_CHANNEL_3) != HAL_OK)
  {
    Error_Handler();
  }
  if (HAL_TIM_IC_ConfigChannel(&htim4, &sConfigIC, TIM_CHANNEL_4) != HAL_OK)
  {
    Error_Handler();
  }

}

static void MX_TIM8_Init(void)
{

  TIM_MasterConfigTypeDef sMasterConfig = {0};
  TIM_IC_InitTypeDef sConfigIC = {0};

  htim8.Instance = TIM8;
  htim8.Init.Prescaler = 0;
  htim8.Init.CounterMode = TIM_COUNTERMODE_UP;
  htim8.Init.Period = 65535;
  htim8.Init.ClockDivision = TIM_CLOCKDIVISION_DIV1;
  htim8.Init.RepetitionCounter = 0;
  htim8.Init.AutoReloadPreload = TIM_AUTORELOAD_PRELOAD_DISABLE;
  if (HAL_TIM_IC_Init(&htim8) != HAL_OK)
  {
    Error_Handler();
  }
  sMasterConfig.MasterOutputTrigger = TIM_TRGO_RESET;
  sMasterConfig.MasterOutputTrigger2 = TIM_TRGO2_RESET;
  sMasterConfig.MasterSlaveMode = TIM_MASTERSLAVEMODE_DISABLE;
  if (HAL_TIMEx_MasterConfigSynchronization(&htim8, &sMasterConfig) != HAL_OK)
  {
    Error_Handler();
  }
  sConfigIC.ICPolarity = TIM_INPUTCHANNELPOLARITY_RISING;
  sConfigIC.ICSelection = TIM_ICSELECTION_DIRECTTI;
  sConfigIC.ICPrescaler = TIM_ICPSC_DIV1;
  sConfigIC.ICFilter = 0;
  if (HAL_TIM_IC_ConfigChannel(&htim8, &sConfigIC, TIM_CHANNEL_4) != HAL_OK)
  {
    Error_Handler();
  }

}

static void MX_TIM15_Init(void)
{

  TIM_MasterConfigTypeDef sMasterConfig = {0};
  TIM_IC_InitTypeDef sConfigIC = {0};

  htim15.Instance = TIM15;
  htim15.Init.Prescaler = 0;
  htim15.Init.CounterMode = TIM_COUNTERMODE_UP;
  htim15.Init.Period = 65535;
  htim15.Init.ClockDivision = TIM_CLOCKDIVISION_DIV1;
  htim15.Init.RepetitionCounter = 0;
  htim15.Init.AutoReloadPreload = TIM_AUTORELOAD_PRELOAD_DISABLE;
  if (HAL_TIM_IC_Init(&htim15) != HAL_OK)
  {
    Error_Handler();
  }
  sMasterConfig.MasterOutputTrigger = TIM_TRGO_RESET;
  sMasterConfig.MasterSlaveMode = TIM_MASTERSLAVEMODE_DISABLE;
  if (HAL_TIMEx_MasterConfigSynchronization(&htim15, &sMasterConfig) != HAL_OK)
  {
    Error_Handler();
  }
  sConfigIC.ICPolarity = TIM_INPUTCHANNELPOLARITY_RISING;
  sConfigIC.ICSelection = TIM_ICSELECTION_DIRECTTI;
  sConfigIC.ICPrescaler = TIM_ICPSC_DIV1;
  sConfigIC.ICFilter = 0;
  if (HAL_TIM_IC_ConfigChannel(&htim15, &sConfigIC, TIM_CHANNEL_2) != HAL_OK)
  {
    Error_Handler();
  }

}

static void MX_USART2_UART_Init(void)
{

  huart2.Instance = USART2;
  huart2.Init.BaudRate = 115200;
  huart2.Init.WordLength = UART_WORDLENGTH_8B;
  huart2.Init.StopBits = UART_STOPBITS_1;
  huart2.Init.Parity = UART_PARITY_NONE;
  huart2.Init.Mode = UART_MODE_TX_RX;
  huart2.Init.HwFlowCtl = UART_HWCONTROL_NONE;
  huart2.Init.OverSampling = UART_OVERSAMPLING_16;
  huart2.Init.OneBitSampling = UART_ONE_BIT_SAMPLE_DISABLE;
  huart2.Init.ClockPrescaler = UART_PRESCALER_DIV1;
  huart2.AdvancedInit.AdvFeatureInit = UART_ADVFEATURE_NO_INIT;
  if (HAL_UART_Init(&huart2) != HAL_OK)
  {
    Error_Handler();
  }
  if (HAL_UARTEx_SetTxFifoThreshold(&huart2, UART_TXFIFO_THRESHOLD_1_8) != HAL_OK)
  {
    Error_Handler();
  }
  if (HAL_UARTEx_SetRxFifoThreshold(&huart2, UART_RXFIFO_THRESHOLD_1_8) != HAL_OK)
  {
    Error_Handler();
  }
  if (HAL_UARTEx_DisableFifoMode(&huart2) != HAL_OK)
  {
    Error_Handler();
  }

}

static void MX_USART3_UART_Init(void)
{

  huart3.Instance = USART3;
  huart3.Init.BaudRate = 115200;
  huart3.Init.WordLength = UART_WORDLENGTH_8B;
  huart3.Init.StopBits = UART_STOPBITS_1;
  huart3.Init.Parity = UART_PARITY_NONE;
  huart3.Init.Mode = UART_MODE_TX_RX;
  huart3.Init.HwFlowCtl = UART_HWCONTROL_RTS_CTS;
  huart3.Init.OverSampling = UART_OVERSAMPLING_16;
  huart3.Init.OneBitSampling = UART_ONE_BIT_SAMPLE_DISABLE;
  huart3.Init.ClockPrescaler = UART_PRESCALER_DIV1;
  huart3.AdvancedInit.AdvFeatureInit = UART_ADVFEATURE_NO_INIT;
  if (HAL_UART_Init(&huart3) != HAL_OK)
  {
    Error_Handler();
  }
  if (HAL_UARTEx_SetTxFifoThreshold(&huart3, UART_TXFIFO_THRESHOLD_1_8) != HAL_OK)
  {
    Error_Handler();
  }
  if (HAL_UARTEx_SetRxFifoThreshold(&huart3, UART_RXFIFO_THRESHOLD_1_8) != HAL_OK)
  {
    Error_Handler();
  }
  if (HAL_UARTEx_DisableFifoMode(&huart3) != HAL_OK)
  {
    Error_Handler();
  }

}

static void MX_USB_OTG_FS_PCD_Init(void)
{

  hpcd_USB_OTG_FS.Instance = USB_OTG_FS;
  hpcd_USB_OTG_FS.Init.dev_endpoints = 6;
  hpcd_USB_OTG_FS.Init.phy_itface = PCD_PHY_EMBEDDED;
  hpcd_USB_OTG_FS.Init.Sof_enable = DISABLE;
  hpcd_USB_OTG_FS.Init.low_power_enable = DISABLE;
  hpcd_USB_OTG_FS.Init.lpm_enable = DISABLE;
  hpcd_USB_OTG_FS.Init.battery_charging_enable = ENABLE;
  hpcd_USB_OTG_FS.Init.use_dedicated_ep1 = DISABLE;
  hpcd_USB_OTG_FS.Init.vbus_sensing_enable = ENABLE;
  if (HAL_PCD_Init(&hpcd_USB_OTG_FS) != HAL_OK)
  {
    Error_Handler();
  }

}

static void MX_GPIO_Init(void)
{
  GPIO_InitTypeDef GPIO_InitStruct = {0};

  /* GPIO Ports Clock Enable */
  __HAL_RCC_GPIOI_CLK_ENABLE();
  __HAL_RCC_GPIOH_CLK_ENABLE();
  __HAL_RCC_GPIOE_CLK_ENABLE();
  __HAL_RCC_GPIOB_CLK_ENABLE();
  __HAL_RCC_GPIOA_CLK_ENABLE();
  __HAL_RCC_GPIOD_CLK_ENABLE();
  __HAL_RCC_GPIOC_CLK_ENABLE();
  __HAL_RCC_GPIOG_CLK_ENABLE();
  HAL_PWREx_EnableVddIO2();
  __HAL_RCC_GPIOF_CLK_ENABLE();

  /*Configure GPIO pin Output Level */
  HAL_GPIO_WritePin(GPIOH, MCU_SMPS_V1_Pin|MCU_SMPS_SW_Pin|MCU_SMPS_V3_Pin|MCU_SMPS_PG_Pin
                          |MCU_SMPS_EN_Pin|MCU_SMPS_V2_Pin, GPIO_PIN_RESET);

  /*Configure GPIO pin Output Level */
  HAL_GPIO_WritePin(TP_RST_GPIO_Port, TP_RST_Pin, GPIO_PIN_RESET);

  /*Configure GPIO pin Output Level */
  HAL_GPIO_WritePin(LCD_PWM_EN_GPIO_Port, LCD_PWM_EN_Pin, GPIO_PIN_RESET);

  /*Configure GPIO pin Output Level */
  HAL_GPIO_WritePin(JOY_SEL_GPIO_Port, JOY_SEL_Pin, GPIO_PIN_RESET);

  /*Configure GPIO pin Output Level */
  HAL_GPIO_WritePin(GPIOG, LED2_Pin|LED1_Pin|LCD_DISP_Pin, GPIO_PIN_RESET);

  /*Configure GPIO pin Output Level */
  HAL_GPIO_WritePin(BL_EN_GPIO_Port, BL_EN_Pin, GPIO_PIN_RESET);

  /*Configure GPIO pins : JOY_RIGHT_Pin JOY_DOWN_Pin TP_INT_Pin JOY_LEFT_Pin
                           JOY_UP_Pin */
  GPIO_InitStruct.Pin = JOY_RIGHT_Pin|JOY_DOWN_Pin|TP_INT_Pin|JOY_LEFT_Pin
                          |JOY_UP_Pin;
  GPIO_InitStruct.Mode = GPIO_MODE_IT_RISING;
  GPIO_InitStruct.Pull = GPIO_NOPULL;
  HAL_GPIO_Init(GPIOI, &GPIO_InitStruct);

  /*Configure GPIO pins : MCU_SMPS_V1_Pin MCU_SMPS_SW_Pin MCU_SMPS_V3_Pin MCU_SMPS_PG_Pin
                           MCU_SMPS_EN_Pin MCU_SMPS_V2_Pin */
  GPIO_InitStruct.Pin = MCU_SMPS_V1_Pin|MCU_SMPS_SW_Pin|MCU_SMPS_V3_Pin|MCU_SMPS_PG_Pin
                          |MCU_SMPS_EN_Pin|MCU_SMPS_V2_Pin;
  GPIO_InitStruct.Mode = GPIO_MODE_OUTPUT_PP;
  GPIO_InitStruct.Pull = GPIO_NOPULL;
  GPIO_InitStruct.Speed = GPIO_SPEED_FREQ_LOW;
  HAL_GPIO_Init(GPIOH, &GPIO_InitStruct);

  /*Configure GPIO pin : TP_RST_Pin */
  GPIO_InitStruct.Pin = TP_RST_Pin;
  GPIO_InitStruct.Mode = GPIO_MODE_OUTPUT_PP;
  GPIO_InitStruct.Pull = GPIO_NOPULL;
  GPIO_InitStruct.Speed = GPIO_SPEED_FREQ_LOW;
  HAL_GPIO_Init(TP_RST_GPIO_Port, &GPIO_InitStruct);

  /*Configure GPIO pin : LCD_PWM_EN_Pin */
  GPIO_InitStruct.Pin = LCD_PWM_EN_Pin;
  GPIO_InitStruct.Mode = GPIO_MODE_OUTPUT_PP;
  GPIO_InitStruct.Pull = GPIO_NOPULL;
  GPIO_InitStruct.Speed = GPIO_SPEED_FREQ_LOW;
  HAL_GPIO_Init(LCD_PWM_EN_GPIO_Port, &GPIO_InitStruct);

  /*Configure GPIO pins : LCD_VSYNC_Pin LCD_R6_Pin LCD_R7_Pin LCD_G6_Pin
                           LCD_G7_Pin LCD_B7_Pin LCD_B6_Pin */
  GPIO_InitStruct.Pin = LCD_VSYNC_Pin|LCD_R6_Pin|LCD_R7_Pin|LCD_G6_Pin
                          |LCD_G7_Pin|LCD_B7_Pin|LCD_B6_Pin;
  GPIO_InitStruct.Mode = GPIO_MODE_AF_PP;
  GPIO_InitStruct.Pull = GPIO_NOPULL;
  GPIO_InitStruct.Speed = GPIO_SPEED_FREQ_LOW;
  GPIO_InitStruct.Alternate = GPIO_AF11_LTDC;
  HAL_GPIO_Init(GPIOE, &GPIO_InitStruct);

  /*Configure GPIO pin : JOY_SEL_Pin */
  GPIO_InitStruct.Pin = JOY_SEL_Pin;
  GPIO_InitStruct.Mode = GPIO_MODE_OUTPUT_PP;
  GPIO_InitStruct.Pull = GPIO_NOPULL;
  GPIO_InitStruct.Speed = GPIO_SPEED_FREQ_LOW;
  HAL_GPIO_Init(JOY_SEL_GPIO_Port, &GPIO_InitStruct);

  /*Configure GPIO pin : BOOT0_Pin */
  GPIO_InitStruct.Pin = BOOT0_Pin;
  GPIO_InitStruct.Mode = GPIO_MODE_INPUT;
  GPIO_InitStruct.Pull = GPIO_NOPULL;
  HAL_GPIO_Init(BOOT0_GPIO_Port, &GPIO_InitStruct);

  /*Configure GPIO pin : MFX_WAKEUP_Pin */
  GPIO_InitStruct.Pin = MFX_WAKEUP_Pin;
  GPIO_InitStruct.Mode = GPIO_MODE_IT_RISING;
  GPIO_InitStruct.Pull = GPIO_NOPULL;
  HAL_GPIO_Init(MFX_WAKEUP_GPIO_Port, &GPIO_InitStruct);

  /*Configure GPIO pins : LED2_Pin LED1_Pin LCD_DISP_Pin */
  GPIO_InitStruct.Pin = LED2_Pin|LED1_Pin|LCD_DISP_Pin;
  GPIO_InitStruct.Mode = GPIO_MODE_OUTPUT_PP;
  GPIO_InitStruct.Pull = GPIO_NOPULL;
  GPIO_InitStruct.Speed = GPIO_SPEED_FREQ_LOW;
  HAL_GPIO_Init(GPIOG, &GPIO_InitStruct);

  /*Configure GPIO pins : LCD_DE_Pin LCD_HSYNC_Pin */
  GPIO_InitStruct.Pin = LCD_DE_Pin|LCD_HSYNC_Pin;
  GPIO_InitStruct.Mode = GPIO_MODE_AF_PP;
  GPIO_InitStruct.Pull = GPIO_NOPULL;
  GPIO_InitStruct.Speed = GPIO_SPEED_FREQ_LOW;
  GPIO_InitStruct.Alternate = GPIO_AF11_LTDC;
  HAL_GPIO_Init(GPIOC, &GPIO_InitStruct);

  /*Configure GPIO pin : STMOD_SPI1_NSS_Pin */
  GPIO_InitStruct.Pin = STMOD_SPI1_NSS_Pin;
  GPIO_InitStruct.Mode = GPIO_MODE_AF_PP;
  GPIO_InitStruct.Pull = GPIO_NOPULL;
  GPIO_InitStruct.Speed = GPIO_SPEED_FREQ_VERY_HIGH;
  GPIO_InitStruct.Alternate = GPIO_AF12_FMC;
  HAL_GPIO_Init(STMOD_SPI1_NSS_GPIO_Port, &GPIO_InitStruct);

  /*Configure GPIO pin : STMOD_INT_Pin */
  GPIO_InitStruct.Pin = STMOD_INT_Pin;
  GPIO_InitStruct.Mode = GPIO_MODE_AF_PP;
  GPIO_InitStruct.Pull = GPIO_NOPULL;
  GPIO_InitStruct.Speed = GPIO_SPEED_FREQ_LOW;
  GPIO_InitStruct.Alternate = GPIO_AF15_EVENTOUT;
  HAL_GPIO_Init(STMOD_INT_GPIO_Port, &GPIO_InitStruct);

  /*Configure GPIO pin : BL_EN_Pin */
  GPIO_InitStruct.Pin = BL_EN_Pin;
  GPIO_InitStruct.Mode = GPIO_MODE_OUTPUT_PP;
  GPIO_InitStruct.Pull = GPIO_NOPULL;
  GPIO_InitStruct.Speed = GPIO_SPEED_FREQ_LOW;
  HAL_GPIO_Init(BL_EN_GPIO_Port, &GPIO_InitStruct);

  /*Configure GPIO pin : LCD_CLK_Pin */
  GPIO_InitStruct.Pin = LCD_CLK_Pin;
  GPIO_InitStruct.Mode = GPIO_MODE_AF_PP;
  GPIO_InitStruct.Pull = GPIO_NOPULL;
  GPIO_InitStruct.Speed = GPIO_SPEED_FREQ_LOW;
  GPIO_InitStruct.Alternate = GPIO_AF11_LTDC;
  HAL_GPIO_Init(LCD_CLK_GPIO_Port, &GPIO_InitStruct);

  /*Configure GPIO pin : LCD_RTC_OUT2_Pin */
  GPIO_InitStruct.Pin = LCD_RTC_OUT2_Pin;
  GPIO_InitStruct.Mode = GPIO_MODE_AF_PP;
  GPIO_InitStruct.Pull = GPIO_NOPULL;
  GPIO_InitStruct.Speed = GPIO_SPEED_FREQ_LOW;
  GPIO_InitStruct.Alternate = GPIO_AF1_LPTIM1;
  HAL_GPIO_Init(LCD_RTC_OUT2_GPIO_Port, &GPIO_InitStruct);

}

/* USER CODE BEGIN 4 */
int8_t bme680I2cRead(uint8_t dev_id, uint8_t reg_addr, uint8_t *reg_data, uint16_t len) {
  int8_t result;

  if (HAL_I2C_Master_Transmit(&hi2c4, (dev_id << 1), &reg_addr, 1, HAL_MAX_DELAY) != HAL_OK) {
    result = -1;
  } else if (HAL_I2C_Master_Receive (&hi2c4, (dev_id << 1) | 0x01, reg_data, len, HAL_MAX_DELAY) != HAL_OK) {
    result = -1;
  } else {
    result = 0;
  }

  return result;
}

int8_t bme680I2cWrite(uint8_t dev_id, uint8_t reg_addr, uint8_t *reg_data, uint16_t len) {
  int8_t result;
  int8_t *buf;

  // Allocate and load I2C transmit buffer
  buf = malloc(len + 1);
  buf[0] = reg_addr;
  memcpy(buf + 1, reg_data, len);

  if (HAL_I2C_Master_Transmit(&hi2c4, (dev_id << 1), (uint8_t *) buf, len + 1, HAL_MAX_DELAY) != HAL_OK) {
    result = -1;
  } else {
    result = 0;
  }

  free(buf);
  return result;
}

// I2C4 De-initialization
void MX_I2C4_DeInit(void) {
  // Ensure idempotence
  if (!i2c4Initialized) { return; }
  i2c4Initialized = false;

  // Deconfigure Analogue filter
  HAL_I2CEx_ConfigAnalogFilter(&hi2c4, I2C_ANALOGFILTER_DISABLE);

  // Deinitialize
  HAL_I2C_DeInit(&hi2c4);
}

size_t noteDebugSerialOutput(const char *message) {
  static const size_t USART2_TIMEOUT = 250;
  size_t result = 0;

  HAL_StatusTypeDef status = HAL_UART_Transmit(&huart2, (uint8_t *)message, strlen(message), USART2_TIMEOUT);
  if (HAL_OK == status) {
    result = sizeof(message);
  } else {
    result = 0;
  }

  return result;
}

const char * noteI2CReceive(uint16_t dev_addr, uint8_t* pBuffer, uint16_t size, uint32_t *available) {
  const char *errstr;
  HAL_StatusTypeDef result;
  uint8_t query_request[2];
  query_request[0] = 0x00;
  query_request[1] = (size & NOTE_I2C_BUFFER_SIZE);

  uint8_t goodbyte = 0;
  uint8_t availbyte = 0;

  result = HAL_I2C_Master_Transmit(&hi2c4, (dev_addr << 1), query_request, sizeof(query_request), HAL_MAX_DELAY);
  switch(result) {
  case HAL_OK:
    errstr = NULL;
    break;
  case HAL_ERROR:
    errstr = ERRSTR("i2c: tranmission error",i2cerr);
    break;
  case HAL_BUSY:
    errstr = ERRSTR("i2c: bus busy",i2cerr);
    break;
  case HAL_TIMEOUT:
    errstr = ERRSTR("i2c: transmission timeout",i2cerr);
    break;
  default:
    errstr = ERRSTR("i2c: unexpected transmission error",i2cerr);
    break;
  }

  // Only receive if we successfully began transmission
  if (!errstr) {
    uint8_t buffer[NOTE_I2C_BUFFER_SIZE];
    int readlen = (size + 2);
    result = HAL_I2C_Master_Receive(&hi2c4, (dev_addr << 1) | 0x01, buffer, readlen, HAL_MAX_DELAY);
    switch(result) {
    case HAL_OK:
      errstr = NULL;
      break;
    case HAL_ERROR:
      errstr = ERRSTR("i2c: read error",i2cerr);
      break;
    case HAL_BUSY:
      errstr = ERRSTR("i2c: bus busy",i2cerr);
      break;
    case HAL_TIMEOUT:
      errstr = ERRSTR("i2c: read timeout",i2cerr);
      break;
    default:
      errstr = ERRSTR("i2c: unexpected read error",i2cerr);
      break;
    }
    if (!errstr) {
      availbyte =buffer[0];
      goodbyte = buffer[1];
      if (goodbyte != size) {
        errstr = ERRSTR("i2c: incorrect amount of data",i2cerr);
      } else {
        memcpy(pBuffer, &buffer[2], buffer[1]);
      }
    }
  }

  if (errstr != NULL) {
    noteDebugSerialOutput(errstr);
    NoteDebugln(errstr);
    return errstr;
  }
  *available = availbyte;
  return NULL;
}

bool noteI2CReset(uint16_t dev_addr) {
  const char *errstr;
  uint8_t buffer[NOTE_I2C_BUFFER_SIZE];
  uint32_t available = 0;

  // Reset the I2C4 Interface
  MX_I2C4_DeInit();
  MX_I2C4_Init();

  // Empty the Notecard send buffer
  errstr = noteI2CReceive(dev_addr, NULL, 0, &available);
  while (!errstr && available) {
    errstr = noteI2CReceive(dev_addr, buffer, available, &available);
    if (errstr) { break; }
  }

  return !errstr;
}

const char * noteI2CTransmit(uint16_t dev_addr, uint8_t* pBuffer, uint16_t size) {
  const char * errstr;
  HAL_StatusTypeDef result;
  uint8_t send_buffer[256];
  send_buffer[0] = (size & NOTE_I2C_BUFFER_SIZE);

  memcpy(&send_buffer[1], pBuffer, send_buffer[0]);
  result = HAL_I2C_Master_Transmit(&hi2c4, (dev_addr << 1), send_buffer, (send_buffer[0] + 1), HAL_MAX_DELAY);
  switch(result) {
  case HAL_OK:
    errstr = NULL;
    break;
  case HAL_ERROR:
    errstr = ERRSTR("i2c: tranmission error",i2cerr);
    break;
  case HAL_BUSY:
    errstr = ERRSTR("i2c: bus busy",i2cerr);
    break;
  case HAL_TIMEOUT:
    errstr = ERRSTR("i2c: transmission timeout",i2cerr);
    break;
  default:
    errstr = ERRSTR("i2c: unexpected transmission error",i2cerr);
    break;
  }

  return errstr;
}
/* USER CODE END 4 */

void Error_Handler(void)
{
}

/************************ (C) COPYRIGHT STMicroelectronics *****END OF FILE****/
